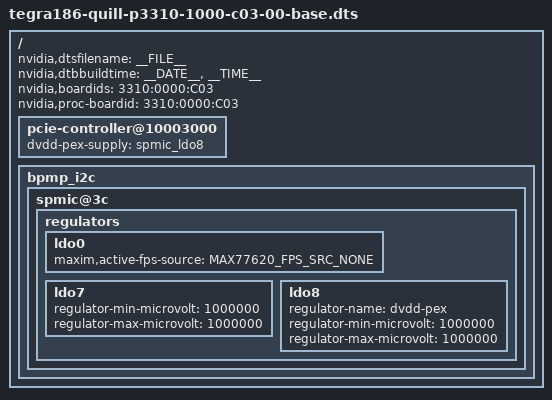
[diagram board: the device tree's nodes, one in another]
/*
 * tegra186-quill-p3310-c03-00-base.dts Quill C03 Board
 *
 * Copyright (c) 2016-2017, NVIDIA CORPORATION. All rights reserved.
 *
 * This program is free software; you can redistribute it and/or modify
 * it under the terms of the GNU General Public License as published by
 * the Free Software Foundation; version 2 of the License.
 *
 * This program is distributed in the hope that it will be useful, but WITHOUT
 * ANY WARRANTY; without even the implied warranty of MERCHANTABILITY or
 * FITNESS FOR A PARTICULAR PURPOSE.  See the GNU General Public License for
 * more details.
 */

#include "tegra186-quill-p3310-1000-a00-00-base.dts"

/ {
	nvidia,dtsfilename = __FILE__;
	nvidia,dtbbuildtime = __DATE__, __TIME__;

        nvidia,boardids = "3310:0000:C03";
        nvidia,proc-boardid = "3310:0000:C03";

	pcie-controller@10003000 {
		dvdd-pex-supply = <&spmic_ldo8>;
	};

	bpmp_i2c {
		spmic@3c {
			regulators {
				ldo0 {
					maxim,active-fps-source = <MAX77620_FPS_SRC_NONE>;
				};

				ldo7 {
					regulator-min-microvolt = <1000000>;
					regulator-max-microvolt = <1000000>;
				};

				ldo8 {
					regulator-name = "dvdd-pex";
					regulator-min-microvolt = <1000000>;
					regulator-max-microvolt = <1000000>;
				};
			};
		};
	};
};
